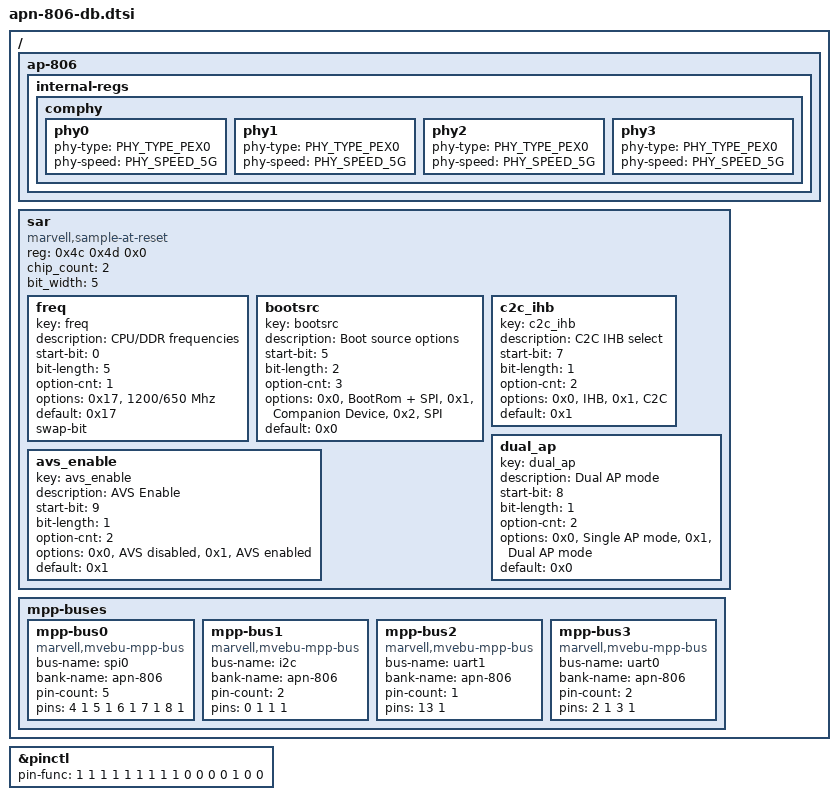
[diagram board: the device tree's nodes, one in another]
/*
 * ***************************************************************************
 * Copyright (C) 2015 Marvell International Ltd.
 * ***************************************************************************
 * This program is free software: you can redistribute it and/or modify it
 * under the terms of the GNU General Public License as published by the Free
 * Software Foundation, either version 2 of the License, or any later version.
 *
 * This program is distributed in the hope that it will be useful,
 * but WITHOUT ANY WARRANTY; without even the implied warranty of
 * MERCHANTABILITY or FITNESS FOR A PARTICULAR PURPOSE.  See the
 * GNU General Public License for more details.
 *
 * You should have received a copy of the GNU General Public License
 * along with this program.  If not, see <http://www.gnu.org/licenses/>.
 * ***************************************************************************
 */

#include <dt-bindings/ddr/ddr_data.h>
#include "apn-806-z1.dtsi"

/ {
	ap-806 {
		internal-regs {
			comphy {
				status = "okay";
				phy0 {
					phy-type = <PHY_TYPE_PEX0>;
					phy-speed = <PHY_SPEED_5G>;
				};
				phy1 {
					phy-type = <PHY_TYPE_PEX0>;
					phy-speed = <PHY_SPEED_5G>;
				};
				phy2 {
					phy-type = <PHY_TYPE_PEX0>;
					phy-speed = <PHY_SPEED_5G>;
				};
				phy3 {
					phy-type = <PHY_TYPE_PEX0>;
					phy-speed = <PHY_SPEED_5G>;
				};
			};
		};
	};
	/* This should go only into devel boards */
	sar {
		compatible = "marvell,sample-at-reset";
		#address-cells = <1>;
		#size-cells = <0>;
		reg = <0x4c 0x4d 0x0>;
		chip_count = <2>;
		bit_width = <5>;

		freq {
			key = "freq";
			description = "CPU/DDR frequencies";
			start-bit = <0>;
			bit-length = <5>;
			option-cnt = <1>;
			options = "0x17", "1200/650 Mhz";
			default = <0x17>;
			swap-bit;
			status = "okay";
		};
		bootsrc {
			key = "bootsrc";
			description = "Boot source options";
			start-bit = <5>;
			bit-length = <2>;
			option-cnt = <3>;
			options = "0x0", "BootRom + SPI",
				"0x1", "Companion Device",
				"0x2", "SPI";
			default = <0x0>;
			status = "okay";
		};
		c2c_ihb {
			key = "c2c_ihb";
			description = "C2C IHB select";
			start-bit = <7>;
			bit-length = <1>;
			option-cnt = <2>;
			options = "0x0", "IHB",
				"0x1", "C2C";
			default = <0x1>;
			status = "okay";
		};
		dual_ap {
			key = "dual_ap";
			description = "Dual AP mode";
			start-bit = <8>;
			bit-length = <1>;
			option-cnt = <2>;
			options = "0x0", "Single AP mode",
				"0x1", "Dual AP mode";
			default = <0x0>;
			status = "okay";
		};
		avs_enable {
			key = "avs_enable";
			description = "AVS Enable";
			start-bit = <9>;
			bit-length = <1>;
			option-cnt = <2>;
			options = "0x0", "AVS disabled",
				"0x1", "AVS enabled";
			default = <0x1>;
			status = "okay";
		};
	};
	/* This should go only into devel boards */
	mpp-buses {
		mpp-bus0 {
			compatible = "marvell,mvebu-mpp-bus";
			bus-name = "spi0";
			bank-name = "apn-806";
			pin-count = <5>;
			pins = <4 1  5 1  6 1  7 1  8 1>;
		};
		mpp-bus1 {
			compatible = "marvell,mvebu-mpp-bus";
			bus-name = "i2c";
			bank-name = "apn-806";
			pin-count = <2>;
			pins = <0 1  1 1>;
		};
		mpp-bus2 {
			/* the RX pin is directly connected to uart1 */
			compatible = "marvell,mvebu-mpp-bus";
			bus-name = "uart1";
			bank-name = "apn-806";
			pin-count = <1>;
			pins = <13 1>;
		};
		mpp-bus3 {
			compatible = "marvell,mvebu-mpp-bus";
			bus-name = "uart0";
			bank-name = "apn-806";
			pin-count = <2>;
			pins = <2 1  3 1>;
		};
	};
};

&pinctl {
		  /* 0 1 2 3 4 5 6 7 8 9 */
	pin-func = < 1 1 1 1 1 1 1 1 1 0
		     0 0 0 1 0 0>;
};

